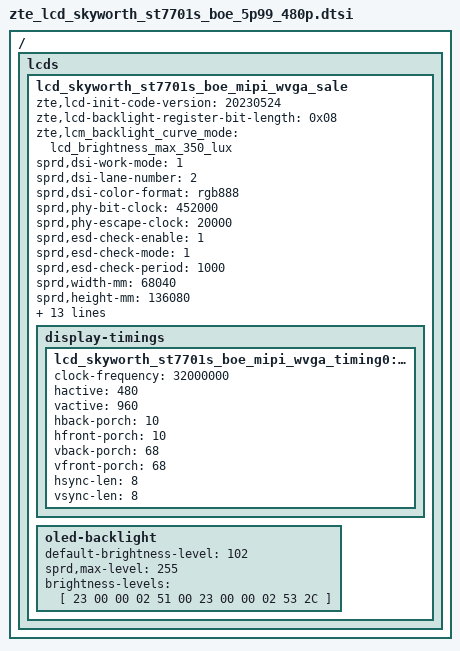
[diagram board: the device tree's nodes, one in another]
/ {
	fragment {
		target-path = "/";
		__overlay__ {
			lcds {
				lcd_skyworth_st7701s_boe_mipi_wvga_sale: lcd_skyworth_st7701s_boe_mipi_wvga_sale {
		zte,lcd-init-code-version = "20230524";
		zte,lcd-backlight-register-bit-length = <0x08>;
		zte,lcm_backlight_curve_mode = "lcd_brightness_max_350_lux";
		sprd,dsi-work-mode = <1>; /* video burst mode*/
		sprd,dsi-lane-number = <2>;
		sprd,dsi-color-format = "rgb888";

		sprd,phy-bit-clock = <452000>;  /* kbps */
		sprd,phy-escape-clock = <20000>;/* kHz */

		sprd,esd-check-enable = <1>;/* 0:close , 1:open */
		sprd,esd-check-mode = <1>;/* 0:REG ,1:TE  */
		sprd,esd-check-period = <1000>;

		sprd,width-mm = <68040>;
		sprd,height-mm = <136080>;
		zte,panel-name = "lcd_skyworth_st7701s_boe_5p99_480p_sale";

		sprd,dphy-taget-val = <5>;

		sprd,reset-on-sequence = <1 5>, <0 5>, <1 120>;
		sprd,reset-off-sequence = <0  120>;

		zte,lcd-close-dynamic-dimming;
		zte,lcd-delay-open-bl-value = <34>;

		sprd,initial-command = [
39 00 00 06 FF 77 01 00 00 13 
39 00 00 02 EF 08
39 00 00 06 FF 77 01 00 00 10 
39 00 00 03 C0 77 00 
39 00 00 03 C1 0B 0C 
39 00 00 03 C2 07 02 
39 00 00 02 CC 30
39 00 00 02 BB 00
39 00 00 02 CA 11
39 00 00 02 BC 01
39 00 00 11 B0 00 06 0F 0A 0F 06 42 09 09 5F 05 12 10 25 2B 12 
39 00 00 11 B1 00 06 0F 0A 0F 05 42 09 09 5F 04 12 10 25 2B 12 
39 00 00 06 FF 77 01 00 00 11 
39 00 00 02 B0 3D
39 00 00 02 B1 27
39 00 00 02 B2 87
39 00 00 02 B3 80
39 00 00 02 B5 47
39 00 00 02 B7 85
39 00 00 02 B8 23
39 00 00 02 B9 10
39 00 00 02 C1 78
39 00 00 02 C2 78
39 0A 00 02 D0 88
39 00 00 04 E0 00 00 02 
39 00 00 0C E1 02 8C 04 8C 01 8C 03 8C 00 44 44 
39 00 00 0E E2 00 00 00 00 00 8C 00 8C 00 8C 00 8C 00 
39 00 00 05 E3 00 00 33 33 
39 00 00 03 E4 44 44 
39 00 00 11 E5 04 CA 8C 8C 06 CC 8C 8C 08 CE 8C 8C 0A D0 8C 8C 
39 00 00 05 E6 00 00 33 33 
39 00 00 03 E7 44 44 
39 00 00 11 E8 03 C9 8C 8C 05 CB 8C 8C 07 CD 8C 8C 09 CF 8C 8C 
39 00 00 08 EB 02 00 E4 E4 44 00 00 
39 00 00 03 EC 00 00 
39 00 00 11 ED FB 10 FA C6 74 5F FF FF FF FF F5 47 6C AF 10 BF 
39 00 00 07 EF 10 0D 04 08 3F 1F 
39 00 00 06 FF 77 01 00 00 13 
39 00 00 03 E8 00 0E 
39 00 00 06 FF 77 01 00 00 00
23 78 00 02 11 00
39 00 00 06 FF 77 01 00 00 13
39 0A 00 03 E8 00 0C 
39 00 00 03 E8 00 00 
39 00 00 06 FF 77 01 00 00 00 
39 00 00 02 51 00
39 00 00 02 53 04
39 00 00 02 35 00
23 14 00 02 29 00
			];
		sprd,sleep-in-command = [
			13 0A 00 01 28
			13 78 00 01 10
			];
		sprd,sleep-out-command = [
			13 78 00 01 11
			13 64 00 01 29
			];

		display-timings {
			lcd_skyworth_st7701s_boe_mipi_wvga_timing0: timing0 {
				clock-frequency = <32000000>;
				hactive = <480>;
				vactive = <960>;
				hback-porch = <10>;
				hfront-porch = <10>;
				vback-porch = <68>;
				vfront-porch = <68>;
				hsync-len = <8>;
				vsync-len = <8>;
			};
		};
		oled-backlight {
			default-brightness-level = <102>;
			sprd,max-level = <255>;
			brightness-levels = [
				23 00 00 02 51 00
				23 00 00 02 53 2C
			];
		};
	};
};};
};};

